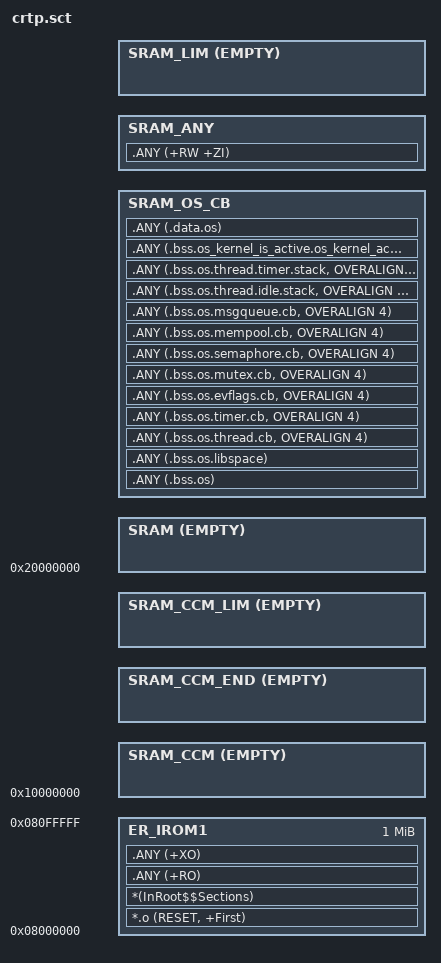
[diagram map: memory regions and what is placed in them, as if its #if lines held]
#! armclang --target=arm-arm-none-eabi -march=armv7-m -E -xc

; *************************************************************
; *** Scatter-Loading Description File generated by uVision ***
; *************************************************************


//-------- <<< Use Configuration Wizard in Context Menu >>> --------------------

// Amount of memory (in bytes) allocated for Stack
// Tailor this value to your application needs
// <h> Stack Configuration
//   <o> Stack Size (in Bytes) <0x0-0xFFFFFFFF:8>
// </h>
#define STACK_SIZE 0x00000200

// <h> Heap Configuration
//   <o>  Heap Size (in Bytes) <0x0-0xFFFFFFFF:8>
// </h>
#define HEAP_SIZE 0x00000200

// <h> Use CCM for stack and heap region
//   <o.0>Use CCM
//   <i> for cortex m4 only
#define CCM_USE 1

// <h> Fill stack and heap region
//   <o.0>Fill stack and heap region as 0xCCCCCCCC
#define FILL_STACKHEAP 1
#if (FILL_STACKHEAP == 1)
    #define STACKHEAP ARM_LIB_STACKHEAP AlignExpr(+0, 8) FILL 0xCCCCCCCC EMPTY STACK_SIZE + HEAP_SIZE
#else
    #define STACKHEAP ARM_LIB_STACKHEAP AlignExpr(+0, 8) EMPTY STACK_SIZE + HEAP_SIZE  
#endif


#if defined(STM32F413xx)
    #define ROM_SIZE     0x00100000
    #define RAM_SIZE     0x00050000
    #define RAM_CCM_SIZE 0x00010000
#elif defined(STM32F411xE)
    #define ROM_SIZE     0x00040000
    #define RAM_SIZE     0x00020000
    #define RAM_CCM_SIZE 0
#else
    #error Device not supported
#endif
#if (RAM_CCM_SIZE == 0)
    #undef CCM_USE
    #define CCM_USE 0
#endif


LR_IROM1 0x08000000 ROM_SIZE  {    ; load region size_region
  ER_IROM1 0x08000000 ROM_SIZE  {  ; load address = execution address
   *.o (RESET, +First)
   *(InRoot$$Sections)
   .ANY (+RO)
   .ANY (+XO)
  }
  
; *************************************************************
; *** CCM RAM                                               ***
; *************************************************************  
  SRAM_CCM 0x10000000 EMPTY 0 {} ; Начало области CCM
  
  ; Начало пользовательских данных в CCM
  #if (CCM_USE == 1)
    STACKHEAP{}
  #endif
  ; Конец пользовательских данных в CCM
  
  SRAM_CCM_END +0 EMPTY 0 {} ; Фактическое окончание области CCM
  
  SRAM_CCM_LIM ImageBase(SRAM_CCM) + RAM_CCM_SIZE EMPTY 0 {} ;  Предел области CCM

; *************************************************************
; *** MAIN RAM                                              ***
; *************************************************************  

  SRAM 0x20000000 EMPTY 0 {}  ; RW data

  #if (CCM_USE != 1)
    STACKHEAP{}
  #endif

  SRAM_OS_CB AlignExpr(+0, 4) {
   .ANY (.bss.os) ; Dynamic memory
   .ANY (.bss.os.libspace)
   .ANY (.bss.os.thread.cb, OVERALIGN 4)
   .ANY (.bss.os.timer.cb, OVERALIGN 4)
   .ANY (.bss.os.evflags.cb, OVERALIGN 4)
   .ANY (.bss.os.mutex.cb, OVERALIGN 4)
   .ANY (.bss.os.semaphore.cb, OVERALIGN 4)
   .ANY (.bss.os.mempool.cb, OVERALIGN 4)
   .ANY (.bss.os.msgqueue.cb, OVERALIGN 4)
   .ANY (.bss.os.thread.idle.stack, OVERALIGN 8)
   .ANY (.bss.os.thread.timer.stack, OVERALIGN 8)
   .ANY (.bss.os_kernel_is_active.os_kernel_active)
   .ANY (.data.os)
  }

  SRAM_ANY +0 {
   .ANY (+RW +ZI)
  }

  SRAM_LIM ImageBase(SRAM) + RAM_SIZE - (ImageBase(SRAM_CCM_END) - ImageBase(SRAM_CCM)) EMPTY 0 {}
}
